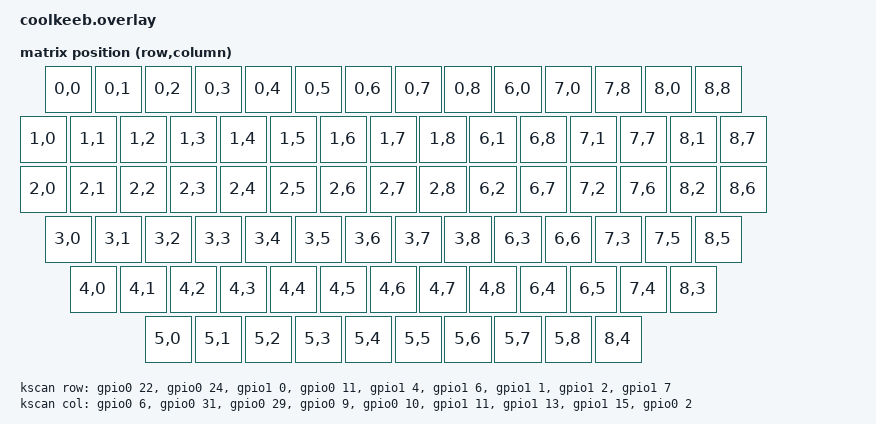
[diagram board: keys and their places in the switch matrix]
// This file was generated from a template. Edit it to match your keyboard.
// See https://zmk.dev/docs/development/hardware-integration/new-shield for more
// instructions.

#include <dt-bindings/zmk/matrix_transform.h>

#include "coolkeeb-layouts.dtsi"

/ {
    chosen {
        zmk,physical-layout = &default_layout;
    };

    kscan: kscan {
        // If the hardware does not use a switch matrix, change this to the
        // appropriate driver and update the properties below to match.
        // See https://zmk.dev/docs/config/kscan for supported key scan drivers.
        compatible = "zmk,kscan-gpio-matrix";
        // Set this to "col2row" or "row2col" to match the hardware. If using
        // "row2col", change the col-gpios to (GPIO_ACTIVE_HIGH | GPIO_PULL_DOWN)
        // and the row-gpios to GPIO_ACTIVE_HIGH.
        diode-direction = "col2row";
        wakeup-source;

        // Replace these comments with the GPIO pins in the matrix.
        // See https://zmk.dev/docs/development/hardware-integration/new-shield#shield-overlays
        col-gpios

            = <&gpio0 6 GPIO_ACTIVE_HIGH>
            , <&gpio0 31 GPIO_ACTIVE_HIGH>
            , <&gpio0 29 GPIO_ACTIVE_HIGH>
            , <&gpio0 9 GPIO_ACTIVE_HIGH>
            , <&gpio0 10 GPIO_ACTIVE_HIGH>
            , <&gpio1 11 GPIO_ACTIVE_HIGH>
            , <&gpio1 13 GPIO_ACTIVE_HIGH>
            , <&gpio1 15 GPIO_ACTIVE_HIGH>
            , <&gpio0 2 GPIO_ACTIVE_HIGH>
            ;

        row-gpios
            = <&gpio0 22 (GPIO_ACTIVE_HIGH | GPIO_PULL_DOWN)>
            , <&gpio0 24 (GPIO_ACTIVE_HIGH | GPIO_PULL_DOWN)>
            , <&gpio1 0 (GPIO_ACTIVE_HIGH | GPIO_PULL_DOWN)>
            , <&gpio0 11 (GPIO_ACTIVE_HIGH | GPIO_PULL_DOWN)>
            , <&gpio1 4 (GPIO_ACTIVE_HIGH | GPIO_PULL_DOWN)>
            , <&gpio1 6 (GPIO_ACTIVE_HIGH | GPIO_PULL_DOWN)>
            , <&gpio1 1 (GPIO_ACTIVE_HIGH | GPIO_PULL_DOWN)>
            , <&gpio1 2 (GPIO_ACTIVE_HIGH | GPIO_PULL_DOWN)>
            , <&gpio1 7 (GPIO_ACTIVE_HIGH | GPIO_PULL_DOWN)>
            ;
    };

    default_transform: default_transform {
        // See https://zmk.dev/docs/development/hardware-integration/new-shield#matrix-transform
        // for how to configure this
        compatible = "zmk,matrix-transform";
        columns = <6>;
        rows = <15>;

        map = <
            RC(0, 0)      RC(0, 1) RC(0, 2) RC(0, 3) RC(0, 4)    RC(0, 5) RC(0, 6) RC(0, 7) RC(0, 8)    RC(6, 0) RC(7, 0) RC(7, 8) RC(8, 0)  RC(8, 8)
            RC(1, 0) RC(1, 1) RC(1, 2) RC(1, 3) RC(1, 4) RC(1, 5) RC(1, 6) RC(1, 7) RC(1, 8) RC(6, 1) RC(6, 8) RC(7, 1) RC(7, 7)   RC(8, 1)  RC(8, 7)
            RC(2, 0)  RC(2, 1) RC(2, 2) RC(2, 3) RC(2, 4) RC(2, 5) RC(2, 6) RC(2, 7) RC(2, 8) RC(6, 2) RC(6, 7) RC(7, 2) RC(7, 6)  RC(8, 2)  RC(8, 6)
            RC(3, 0)   RC(3, 1) RC(3, 2) RC(3, 3) RC(3, 4) RC(3, 5) RC(3, 6) RC(3, 7) RC(3, 8) RC(6, 3) RC(6, 6) RC(7, 3)     RC(7, 5)       RC(8, 5)
            RC(4, 0)    RC(4, 1) RC(4, 2) RC(4, 3) RC(4, 4) RC(4, 5) RC(4, 6) RC(4, 7) RC(4, 8) RC(6, 4) RC(6, 5)     RC(7, 4)        RC(8, 3)
            RC(5, 0)    RC(5, 1)    RC(5, 2)         RC(5, 3)         RC(5, 4) RC(5, 5) RC(5, 6)                             RC(5, 7) RC(5, 8) RC(8, 4)
        >;
    };
};
